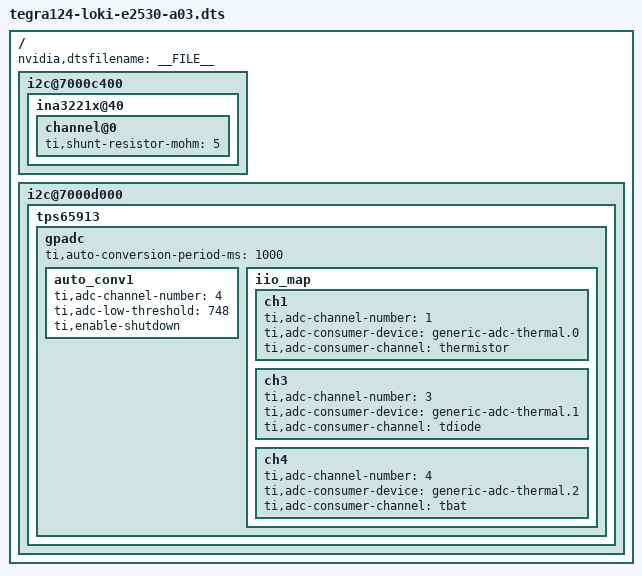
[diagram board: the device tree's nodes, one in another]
#include "tegra124-loki-common.dtsi"
#include "tegra124-platforms/tegra124-loki-powermon-e2530-a01.dtsi"
#include "tegra124-platforms/tegra124-loki-pmic-e2530-0000-a01.dtsi"
#include "tegra124-platforms/tegra124-loki-fixed-e2530-0000-a00.dtsi"

/ {
	nvidia,dtsfilename = __FILE__;

	i2c@7000c400 {
		ina3221x@40 {
			channel@0 {
				ti,shunt-resistor-mohm = <5>;
			};
		};
	};

	i2c@7000d000 {
		tps65913 {
			gpadc {
				ti,auto-conversion-period-ms = <1000>;
				auto_conv1 {
					ti,adc-channel-number = <4>;
					ti,adc-low-threshold = <748>;
					ti,enable-shutdown;
				};

				iio_map {
					ch1 {
						ti,adc-channel-number = <1>;
						ti,adc-consumer-device = "generic-adc-thermal.0";
						ti,adc-consumer-channel ="thermistor";
					};

					ch3 {
						ti,adc-channel-number = <3>;
						ti,adc-consumer-device = "generic-adc-thermal.1";
						ti,adc-consumer-channel ="tdiode";
					};

					ch4 {
						ti,adc-channel-number = <4>;
						ti,adc-consumer-device = "generic-adc-thermal.2";
						ti,adc-consumer-channel ="tbat";
					};
				};
			};
		};
	};
};
